VERSION ""

NS_ :

BS_:

BU_: EDT TMU CGW

BO_ 262 CGW_EDT_E_OTA_ROLLBACK: 1 CGW
 SG_ sg_ota_rollback : 0|8@1- (1,0) [-128|127] "" Vector__XXX

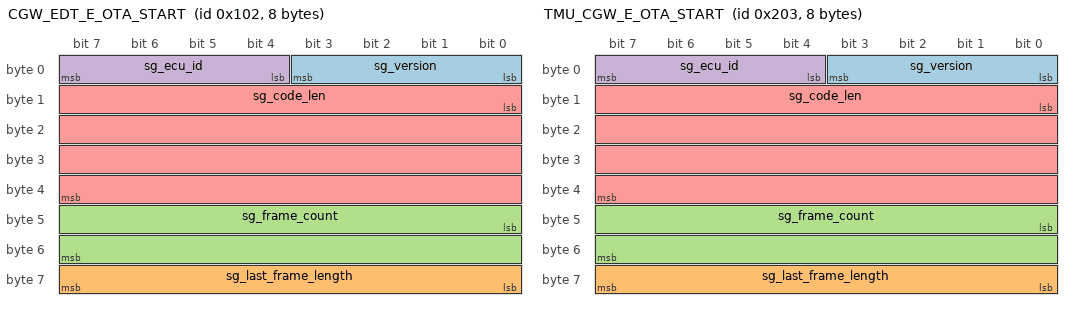
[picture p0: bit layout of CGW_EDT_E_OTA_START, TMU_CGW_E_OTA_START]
BO_ 258 CGW_EDT_E_OTA_START: 8 Vector__XXX
 SG_ sg_version : 0|4@1+ (1,0) [0|15] "" Vector__XXX
 SG_ sg_last_frame_length : 56|8@1+ (1,0) [0|255] "" Vector__XXX
 SG_ sg_frame_count : 40|16@1+ (1,0) [0|65535] "" Vector__XXX
 SG_ sg_ecu_id : 4|4@1+ (1,0) [0|15] "" Vector__XXX
 SG_ sg_code_len : 8|32@1+ (1,0) [0|16777215] "" Vector__XXX

BO_ 515 TMU_CGW_E_OTA_START: 8 Vector__XXX
 SG_ sg_version : 0|4@1+ (1,0) [0|15] "" Vector__XXX
 SG_ sg_last_frame_length : 56|8@1+ (1,0) [0|255] "" Vector__XXX
 SG_ sg_frame_count : 40|16@1+ (1,0) [0|65535] "" Vector__XXX
 SG_ sg_ecu_id : 4|4@1+ (1,0) [0|15] "" Vector__XXX
 SG_ sg_code_len : 8|32@1+ (1,0) [0|16777215] "" Vector__XXX

BO_ 260 CGW_TMU_E_OTA_REQ: 1 CGW
 SG_ sg_request : 0|8@1- (1,0) [0|10] ""  TMU

BO_ 259 CGW_TMU_E_OTA_RESULT: 2 CGW
 SG_ sg_edt_ota_result : 0|8@1- (1,0) [0|1] ""  TMU

BO_ 261 CGW_EDT_PE_OTA_DATA: 64 CGW
 SG_ sg_data : 0|8@1+ (1,0) [0|255] ""  EDT

BO_ 514 TMU_CGW_E_OTA_REQ: 1 TMU
 SG_ sq_request : 0|8@1- (1,0) [0|10] ""  CGW

BO_ 513 TMU_Version: 1 Vector__XXX
 SG_ sg_tmu_version : 0|8@1- (1,0) [0|10] "" Vector__XXX

BO_ 257 CGW_TMU_E_VER_INFO: 1 CGW
 SG_ sg_cgw_version : 0|8@1- (1,0) [0|127] ""  TMU

BO_ 769 EDT_TMU_E_VER_INFO: 1 EDT
 SG_ sg_edt_version : 0|8@1- (1,0) [0|127] ""  TMU

BO_ 771 EDT_CGW_E_OTA_RESULT: 2 EDT
 SG_ sg_edt_ota_result : 0|8@1- (1,0) [0|1] ""  CGW

BO_ 516 TMU_CGW_PE_OTA_DATA: 64 TMU
 SG_ sg_data : 0|8@1+ (1,0) [0|255] ""  CGW

BA_DEF_ BO_  "CANFD_BRS" ENUM  "0","1";
BA_DEF_  "DBName" STRING ;
BA_DEF_  "BusType" STRING ;
BA_DEF_ BO_  "VFrameFormat" ENUM  "StandardCAN","ExtendedCAN","reserved","reserved","reserved","reserved","reserved","reserved","reserved","reserved","reserved","reserved","reserved","reserved","StandardCAN_FD","ExtendedCAN_FD";
BA_DEF_DEF_  "CANFD_BRS" "1";
BA_DEF_DEF_  "DBName" "";
BA_DEF_DEF_  "BusType" "";
BA_DEF_DEF_  "VFrameFormat" "StandardCAN";
BA_ "BusType" "CAN FD";
BA_ "DBName" "test1";
BA_ "VFrameFormat" BO_ 262 14;
BA_ "VFrameFormat" BO_ 258 14;
BA_ "VFrameFormat" BO_ 515 14;
BA_ "VFrameFormat" BO_ 260 14;
BA_ "VFrameFormat" BO_ 259 14;
BA_ "VFrameFormat" BO_ 261 14;
BA_ "VFrameFormat" BO_ 514 14;
BA_ "VFrameFormat" BO_ 257 14;
BA_ "VFrameFormat" BO_ 769 14;
BA_ "VFrameFormat" BO_ 771 14;
BA_ "VFrameFormat" BO_ 516 14;
